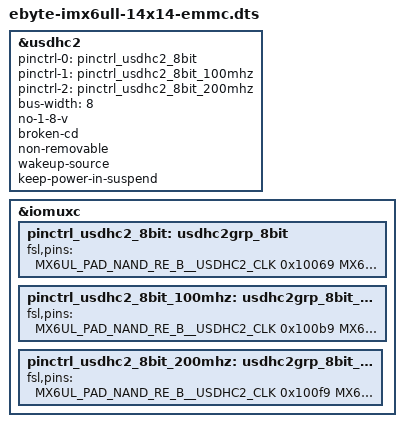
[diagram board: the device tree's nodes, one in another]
/*
 * Copyright 2019 NXP
 *
 * This program is free software; you can redistribute it and/or
 * modify it under the terms of the GNU General Public License
 * as published by the Free Software Foundation; either version 2
 * of the License, or (at your option) any later version.
 */

#include "ebyte-imx6ull-14x14-base.dtsi"

&usdhc2 {
	pinctrl-names = "default", "state_100mhz", "state_200mhz";
	pinctrl-0 = <&pinctrl_usdhc2_8bit>;
	pinctrl-1 = <&pinctrl_usdhc2_8bit_100mhz>;
	pinctrl-2 = <&pinctrl_usdhc2_8bit_200mhz>;
	bus-width = <8>;
	no-1-8-v;
	broken-cd;
	non-removable;
	wakeup-source;
	keep-power-in-suspend;
	status = "okay";
};

&iomuxc {
	pinctrl_usdhc2_8bit: usdhc2grp_8bit {
		fsl,pins = <
			MX6UL_PAD_NAND_RE_B__USDHC2_CLK     0x10069
			MX6UL_PAD_NAND_WE_B__USDHC2_CMD     0x17059
			MX6UL_PAD_NAND_DATA00__USDHC2_DATA0 0x17059
			MX6UL_PAD_NAND_DATA01__USDHC2_DATA1 0x17059
			MX6UL_PAD_NAND_DATA02__USDHC2_DATA2 0x17059
			MX6UL_PAD_NAND_DATA03__USDHC2_DATA3 0x17059
			MX6UL_PAD_NAND_DATA04__USDHC2_DATA4 0x17059
			MX6UL_PAD_NAND_DATA05__USDHC2_DATA5 0x17059
			MX6UL_PAD_NAND_DATA06__USDHC2_DATA6 0x17059
			MX6UL_PAD_NAND_DATA07__USDHC2_DATA7 0x17059
			MX6UL_PAD_NAND_ALE__USDHC2_RESET_B  0x17059
		>;
	};

	pinctrl_usdhc2_8bit_100mhz: usdhc2grp_8bit_100mhz {
		fsl,pins = <
			MX6UL_PAD_NAND_RE_B__USDHC2_CLK     0x100b9
			MX6UL_PAD_NAND_WE_B__USDHC2_CMD     0x170b9
			MX6UL_PAD_NAND_DATA00__USDHC2_DATA0 0x170b9
			MX6UL_PAD_NAND_DATA01__USDHC2_DATA1 0x170b9
			MX6UL_PAD_NAND_DATA02__USDHC2_DATA2 0x170b9
			MX6UL_PAD_NAND_DATA03__USDHC2_DATA3 0x170b9
			MX6UL_PAD_NAND_DATA04__USDHC2_DATA4 0x170b9
			MX6UL_PAD_NAND_DATA05__USDHC2_DATA5 0x170b9
			MX6UL_PAD_NAND_DATA06__USDHC2_DATA6 0x170b9
			MX6UL_PAD_NAND_DATA07__USDHC2_DATA7 0x170b9
			MX6UL_PAD_NAND_ALE__USDHC2_RESET_B  0x170b9
		>;
	};

	pinctrl_usdhc2_8bit_200mhz: usdhc2grp_8bit_200mhz {
		fsl,pins = <
			MX6UL_PAD_NAND_RE_B__USDHC2_CLK     0x100f9
			MX6UL_PAD_NAND_WE_B__USDHC2_CMD     0x170f9
			MX6UL_PAD_NAND_DATA00__USDHC2_DATA0 0x170f9
			MX6UL_PAD_NAND_DATA01__USDHC2_DATA1 0x170f9
			MX6UL_PAD_NAND_DATA02__USDHC2_DATA2 0x170f9
			MX6UL_PAD_NAND_DATA03__USDHC2_DATA3 0x170f9
			MX6UL_PAD_NAND_DATA04__USDHC2_DATA4 0x170f9
			MX6UL_PAD_NAND_DATA05__USDHC2_DATA5 0x170f9
			MX6UL_PAD_NAND_DATA06__USDHC2_DATA6 0x170f9
			MX6UL_PAD_NAND_DATA07__USDHC2_DATA7 0x170f9
			MX6UL_PAD_NAND_ALE__USDHC2_RESET_B  0x170f9
		>;
	};
};
